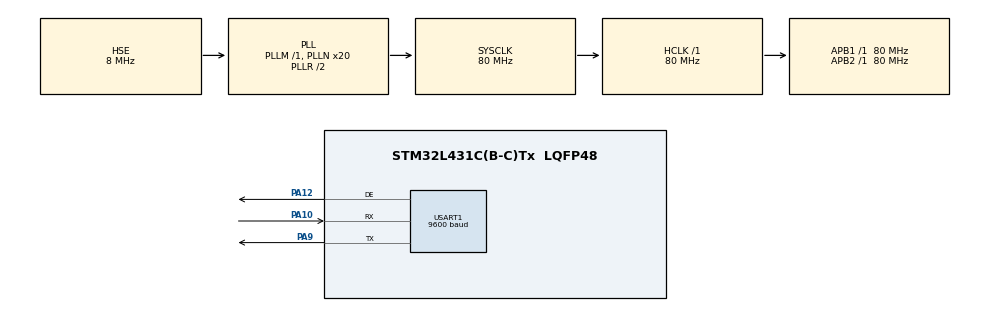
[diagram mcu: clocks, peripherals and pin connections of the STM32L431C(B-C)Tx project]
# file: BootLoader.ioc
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CRC.CRCLength=CRC_POLYLENGTH_16B
CRC.DefaultInitValueUse=DEFAULT_INIT_VALUE_DISABLE
CRC.DefaultPolynomialUse=DEFAULT_POLYNOMIAL_DISABLE
CRC.InputDataInversionMode=CRC_INPUTDATA_INVERSION_NONE
Mcu.Family=STM32L4
Mcu.Name=STM32L431C(B-C)Tx
Mcu.Package=LQFP48
NVIC.PriorityGroup=NVIC_PRIORITYGROUP_4
NVIC.USART1_IRQn=true\:0\:0\:false\:false\:true\:true\:true
PA10.Mode=Asynchronous
PA10.Signal=USART1_RX
PA12.Mode=Hardware Flow Control (RS485)
PA12.Signal=USART1_DE
PA9.Mode=Asynchronous
PA9.Signal=USART1_TX
PH0-OSC_IN\ (PH0).Mode=HSE-External-Oscillator
PH0-OSC_IN\ (PH0).Signal=RCC_OSC_IN
PH1-OSC_OUT\ (PH1).Mode=HSE-External-Oscillator
PH1-OSC_OUT\ (PH1).Signal=RCC_OSC_OUT
ProjectManager.HeapSize=0x200
ProjectManager.StackSize=0x400
ProjectManager.TargetToolchain=MDK-ARM V5
RCC.ADCFreq_Value=32000000
RCC.AHBFreq_Value=80000000
RCC.APB1Freq_Value=80000000
RCC.APB1TimFreq_Value=80000000
RCC.APB2Freq_Value=80000000
RCC.APB2TimFreq_Value=80000000
RCC.CortexFreq_Value=80000000
RCC.HCLKFreq_Value=80000000
RCC.HSE_VALUE=8000000
RCC.HSI48_VALUE=48000000
RCC.HSI_VALUE=16000000
RCC.LSE_VALUE=32768
RCC.MSI_VALUE=4000000
RCC.PLLN=20
RCC.PLLSourceVirtual=RCC_PLLSOURCE_HSE
RCC.SYSCLKFreq_VALUE=80000000
RCC.SYSCLKSource=RCC_SYSCLKSOURCE_PLLCLK
RCC.VCOOutputFreq_Value=160000000
USART1.BaudRate=9600
USART1.VirtualMode-Asynchronous=VM_ASYNC
USART1.VirtualMode-Hardware\ Flow\ Control\ (RS485)=VM_ASYNC
VP_CRC_VS_CRC.Mode=CRC_Activate
board=custom

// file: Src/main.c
/* USER CODE BEGIN Header */
/**
  ******************************************************************************
  * @file           : main.c
  * @brief          : Main program body
  ******************************************************************************
  * @attention
  *
  * <h2><center>&copy; Copyright (c) 2019 STMicroelectronics.
  * All rights reserved.</center></h2>
  *
  * This software component is licensed by ST under BSD 3-Clause license,
  * the "License"; You may not use this file except in compliance with the
  * License. You may obtain a copy of the License at:
  *                        opensource.org/licenses/BSD-3-Clause
  *
  ******************************************************************************
  */
/* USER CODE END Header */

#include "main.h"

/* USER CODE BEGIN Includes */
#include "common.h"
#include "flash_if.h"
#include "menu.h"
#include "ymodem.h"
/* USER CODE END Includes */

CRC_HandleTypeDef hcrc;

UART_HandleTypeDef huart1;

void SystemClock_Config(void);
static void MX_GPIO_Init(void);
static void MX_CRC_Init(void);
static void MX_USART1_UART_Init(void);

/* USER CODE BEGIN 0 */
extern pFunction JumpToApplication;
extern uint32_t JumpAddress;
uint8_t Buff_Temp[1]= {0};
uint8_t Rx_count=0;
uint8_t Rx_Buf[3]={0};
uint8_t isGotoBootloader = 0;
uint8_t i = 5;
/* USER CODE END 0 */

int main(void)
{

  /* MCU Configuration--------------------------------------------------------*/

  /* Reset of all peripherals, Initializes the Flash interface and the Systick. */
  HAL_Init();

  /* Configure the system clock */
  SystemClock_Config();

  /* Initialize all configured peripherals */
  MX_GPIO_Init();
  MX_CRC_Init();
  MX_USART1_UART_Init();
  /* USER CODE BEGIN 2 */
	FLASH_If_Init();
	HAL_UART_Receive_IT(&huart1, Buff_Temp, 1);//使能接收中断
	Serial_PutString((uint8_t*)"DO Probe Startup\r\n\n");
	Serial_PutString((uint8_t*)"Boot to App in 5 sec later\r\n\n");
	Serial_PutString((uint8_t*)"Press abc to interrupt ......\r\n\n");
	Rx_count=0;
	while(i)
	{
		if((Rx_Buf[0]=='a')&&((Rx_Buf[1]=='b'))&&((Rx_Buf[2]=='c')))
		{
			isGotoBootloader=1;
			Rx_count = 0;
			break;
		}
		HAL_Delay(1000);
		i--;
	}
	if (isGotoBootloader)
  {
    /* Display main menu */
    Main_Menu ();
  }
  else
  {
		Serial_PutString((uint8_t*)"Jump to App...\r\n");
		/* Keep the user application running */

    /* Test if user code is programmed starting from address "APPLICATION_ADDRESS" */
    if (((*(__IO uint32_t*)APPLICATION_ADDRESS) & 0x2FFE0000 ) == 0x20000000)
    {
      /* Jump to user application */
      JumpAddress = *(__IO uint32_t*) (APPLICATION_ADDRESS + 4);
      JumpToApplication = (pFunction) JumpAddress;

      /* Initialize user application's Stack Pointer */
      __set_MSP(*(__IO uint32_t*) APPLICATION_ADDRESS);

      /* Jump to application */
      JumpToApplication();
    }
  }
  /* USER CODE END 2 */

  /* Infinite loop */
  while (1)
  {

  }
}

void SystemClock_Config(void)
{
  RCC_OscInitTypeDef RCC_OscInitStruct = {0};
  RCC_ClkInitTypeDef RCC_ClkInitStruct = {0};
  RCC_PeriphCLKInitTypeDef PeriphClkInit = {0};

  /** Initializes the CPU, AHB and APB busses clocks
  */
  RCC_OscInitStruct.OscillatorType = RCC_OSCILLATORTYPE_HSE;
  RCC_OscInitStruct.HSEState = RCC_HSE_ON;
  RCC_OscInitStruct.PLL.PLLState = RCC_PLL_ON;
  RCC_OscInitStruct.PLL.PLLSource = RCC_PLLSOURCE_HSE;
  RCC_OscInitStruct.PLL.PLLM = 1;
  RCC_OscInitStruct.PLL.PLLN = 20;
  RCC_OscInitStruct.PLL.PLLP = RCC_PLLP_DIV7;
  RCC_OscInitStruct.PLL.PLLQ = RCC_PLLQ_DIV2;
  RCC_OscInitStruct.PLL.PLLR = RCC_PLLR_DIV2;
  if (HAL_RCC_OscConfig(&RCC_OscInitStruct) != HAL_OK)
  {
    Error_Handler();
  }
  /** Initializes the CPU, AHB and APB busses clocks
  */
  RCC_ClkInitStruct.ClockType = RCC_CLOCKTYPE_HCLK|RCC_CLOCKTYPE_SYSCLK
                              |RCC_CLOCKTYPE_PCLK1|RCC_CLOCKTYPE_PCLK2;
  RCC_ClkInitStruct.SYSCLKSource = RCC_SYSCLKSOURCE_PLLCLK;
  RCC_ClkInitStruct.AHBCLKDivider = RCC_SYSCLK_DIV1;
  RCC_ClkInitStruct.APB1CLKDivider = RCC_HCLK_DIV1;
  RCC_ClkInitStruct.APB2CLKDivider = RCC_HCLK_DIV1;

  if (HAL_RCC_ClockConfig(&RCC_ClkInitStruct, FLASH_LATENCY_4) != HAL_OK)
  {
    Error_Handler();
  }
  PeriphClkInit.PeriphClockSelection = RCC_PERIPHCLK_USART1;
  PeriphClkInit.Usart1ClockSelection = RCC_USART1CLKSOURCE_PCLK2;
  if (HAL_RCCEx_PeriphCLKConfig(&PeriphClkInit) != HAL_OK)
  {
    Error_Handler();
  }
  /** Configure the main internal regulator output voltage
  */
  if (HAL_PWREx_ControlVoltageScaling(PWR_REGULATOR_VOLTAGE_SCALE1) != HAL_OK)
  {
    Error_Handler();
  }
}

static void MX_CRC_Init(void)
{

  hcrc.Instance = CRC;
  hcrc.Init.DefaultPolynomialUse = DEFAULT_POLYNOMIAL_DISABLE;
	hcrc.Init.GeneratingPolynomial = 0x1021;
  hcrc.Init.CRCLength = CRC_POLYLENGTH_16B;

  hcrc.Init.DefaultInitValueUse = DEFAULT_INIT_VALUE_DISABLE;
  hcrc.Init.InitValue = 0;

  hcrc.Init.InputDataInversionMode = CRC_INPUTDATA_INVERSION_NONE;

  hcrc.Init.OutputDataInversionMode = CRC_OUTPUTDATA_INVERSION_DISABLE;
  hcrc.InputDataFormat = CRC_INPUTDATA_FORMAT_BYTES;
  if (HAL_CRC_Init(&hcrc) != HAL_OK)
  {
    Error_Handler();
  }

}

static void MX_USART1_UART_Init(void)
{

  huart1.Instance = USART1;
  huart1.Init.BaudRate = 9600;
  huart1.Init.WordLength = UART_WORDLENGTH_8B;
  huart1.Init.StopBits = UART_STOPBITS_1;
  huart1.Init.Parity = UART_PARITY_NONE;
  huart1.Init.Mode = UART_MODE_TX_RX;
  huart1.Init.HwFlowCtl = UART_HWCONTROL_NONE;
  //huart1.Init.OverSampling = UART_OVERSAMPLING_16;
  //huart1.Init.OneBitSampling = UART_ONE_BIT_SAMPLE_DISABLE;
  huart1.AdvancedInit.AdvFeatureInit = UART_ADVFEATURE_RXOVERRUNDISABLE_INIT | UART_ADVFEATURE_SWAP_INIT;
	huart1.AdvancedInit.OverrunDisable = UART_ADVFEATURE_OVERRUN_DISABLE;
	 huart1.AdvancedInit.Swap = UART_ADVFEATURE_SWAP_ENABLE;
  if (HAL_RS485Ex_Init(&huart1, UART_DE_POLARITY_HIGH, 0, 0) != HAL_OK)
  {
    Error_Handler();
  }

}

static void MX_GPIO_Init(void)
{

  /* GPIO Ports Clock Enable */
  __HAL_RCC_GPIOH_CLK_ENABLE();
  __HAL_RCC_GPIOA_CLK_ENABLE();

}

/* USER CODE BEGIN 4 */
void HAL_UART_RxCpltCallback(UART_HandleTypeDef *huart)
{
	if(huart->Instance == USART1)
	{
		Rx_Buf[Rx_count++] = Buff_Temp[0];
		if(Rx_count == 3)
		{
				Rx_count=3;
		}
		else
		{
			HAL_UART_Receive_IT(&huart1,Buff_Temp , 1);
		}
	}
}
/* USER CODE END 4 */

void Error_Handler(void)
{
}

/************************ (C) COPYRIGHT STMicroelectronics *****END OF FILE****/
